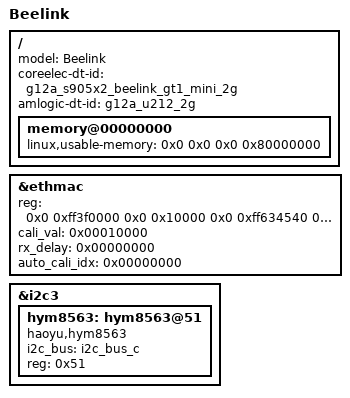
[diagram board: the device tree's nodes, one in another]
#include "g12a_s905x2_beelink_gt_mini_a_2g.dts"

/{
	model = "Beelink";
	coreelec-dt-id = "g12a_s905x2_beelink_gt1_mini_2g";
	amlogic-dt-id = "g12a_u212_2g";

	memory@00000000 {
		linux,usable-memory = <0x0 0x0 0x0 0x80000000>;
	};
};

&ethmac {
	reg = <0x0 0xff3f0000 0x0 0x10000
		0x0 0xff634540 0x0 0x8
		0x0 0xff64c000 0x0 0xa0>;
	reg-names = "eth_base", "eth_cfg", "eth_pll";
	/delete-property/ pinctrl-1;
	cali_val = <0x00010000>;
	rx_delay = <0x00000000>;
	auto_cali_idx = <0x00000000>;
};

&i2c3 {
	status = "okay";
	hym8563: hym8563@51 {
		compatible = "haoyu,hym8563";
		i2c_bus = "i2c_bus_c";
		#clock-cells = <0x00000000>;
		status = "okay";
		reg = <0x51>;
	};
};
